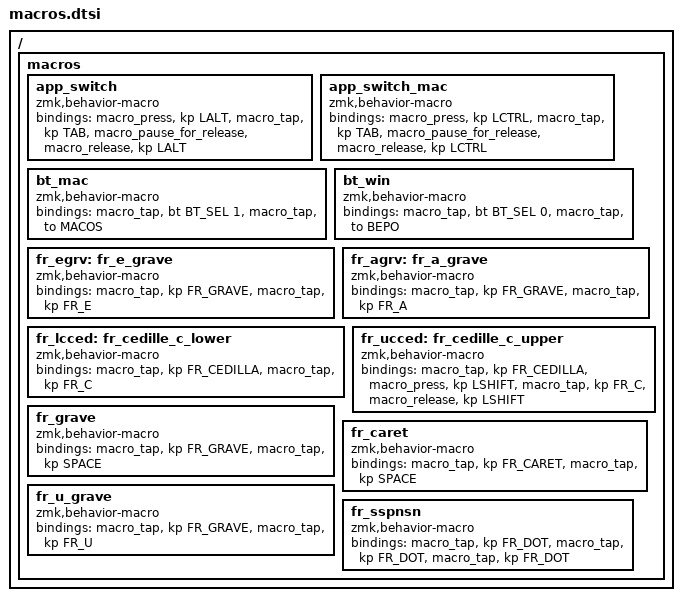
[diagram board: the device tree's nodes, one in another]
/ {
    macros {
        app_switch: app_switch {
            compatible = "zmk,behavior-macro";
            #binding-cells = <0>;
            bindings
                = <&macro_press &kp LALT>
                , <&macro_tap &kp TAB>
                , <&macro_pause_for_release>
                , <&macro_release &kp LALT>;
        };
        app_switch_mac: app_switch_mac {
            compatible = "zmk,behavior-macro";
            #binding-cells = <0>;
            bindings
                = <&macro_press &kp LCTRL>
                , <&macro_tap &kp TAB>
                , <&macro_pause_for_release>
                , <&macro_release &kp LCTRL>;
        };
        bt_mac: bt_mac {
            compatible = "zmk,behavior-macro";
            #binding-cells = <0>;
            bindings
                = <&macro_tap &bt BT_SEL 1>
                , <&macro_tap &to MACOS>;
        };
        bt_win: bt_win {
            compatible = "zmk,behavior-macro";
            #binding-cells = <0>;
            bindings
                = <&macro_tap &bt BT_SEL 0>
                , <&macro_tap &to BEPO>;
        };
        fr_egrv: fr_e_grave {
            compatible = "zmk,behavior-macro";
            #binding-cells = <0>;
            bindings
                = <&macro_tap &kp FR_GRAVE>
                , <&macro_tap &kp FR_E>;
        };
        fr_agrv: fr_a_grave {
            compatible = "zmk,behavior-macro";
            #binding-cells = <0>;
            bindings
                = <&macro_tap &kp FR_GRAVE>
                , <&macro_tap &kp FR_A>;
        };
        fr_lcced: fr_cedille_c_lower {
            compatible = "zmk,behavior-macro";
            #binding-cells = <0>;
            bindings
                = <&macro_tap &kp FR_CEDILLA>
                , <&macro_tap &kp FR_C>;
        };
        fr_ucced: fr_cedille_c_upper {
            compatible = "zmk,behavior-macro";
            #binding-cells = <0>;
            bindings
                = <&macro_tap &kp FR_CEDILLA>
                , <&macro_press &kp LSHIFT>
                , <&macro_tap &kp FR_C>
                , <&macro_release &kp LSHIFT>;
        };
        fr_grave: fr_grave {
            compatible = "zmk,behavior-macro";
            #binding-cells = <0>;
            bindings
                = <&macro_tap &kp FR_GRAVE>
                , <&macro_tap &kp SPACE>;
        };    
        fr_caret: fr_caret {
            compatible = "zmk,behavior-macro";
            #binding-cells = <0>;
            bindings
                = <&macro_tap &kp FR_CARET>
                , <&macro_tap &kp SPACE>;
        };
        fr_u_grave: fr_u_grave {
            compatible = "zmk,behavior-macro";
            #binding-cells = <0>;
            bindings
                = <&macro_tap &kp FR_GRAVE>
                , <&macro_tap &kp FR_U>;
        };               
        fr_sspnsn: fr_sspnsn {
            compatible = "zmk,behavior-macro";
            #binding-cells = <0>;
            bindings
                = <&macro_tap &kp FR_DOT>
                , <&macro_tap &kp FR_DOT>
                , <&macro_tap &kp FR_DOT>;
        };               
    };
};
